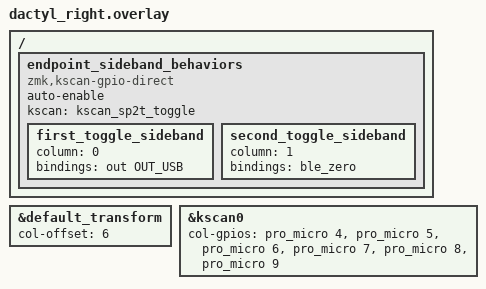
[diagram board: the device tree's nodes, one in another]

/*
 * Copyright (c) 2020 Pete Johanson
 *
 * SPDX-License-Identifier: MIT
 */

#include "dactyl.dtsi"

&default_transform {
    col-offset = <6>;
};

&kscan0 {
    col-gpios
        = <&pro_micro 4 GPIO_ACTIVE_HIGH>
        , <&pro_micro 5 GPIO_ACTIVE_HIGH>
        , <&pro_micro 6 GPIO_ACTIVE_HIGH>
        , <&pro_micro 7 GPIO_ACTIVE_HIGH>
        , <&pro_micro 8 GPIO_ACTIVE_HIGH>
        , <&pro_micro 9 GPIO_ACTIVE_HIGH>
        ;
};

/{
    endpoint_sideband_behaviors {
        compatible = "zmk,kscan-gpio-direct";

        auto-enable;
        kscan = <&kscan_sp2t_toggle>;

        first_toggle_sideband: first_toggle_sideband {
            column = <0>;
            bindings = <&out OUT_USB>;
        };

        second_toggle_sideband: second_toggle_sideband {
            column = <1>;
            bindings = <&ble_zero>;
        };
    };
}
